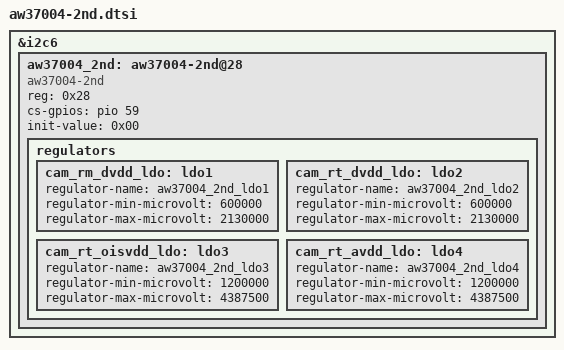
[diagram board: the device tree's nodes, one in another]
&i2c6{
    aw37004_2nd: aw37004-2nd@28 {
        status = "okay";
        compatible = "aw37004-2nd";
        reg = <0x28>;
        cs-gpios = <&pio 59 0>;
        init-value = <0x00>;
        regulators{
            cam_rm_dvdd_ldo: ldo1 {
                regulator-name = "aw37004_2nd_ldo1";
                regulator-min-microvolt = <600000>;
                regulator-max-microvolt = <2130000>;
            };

            cam_rt_dvdd_ldo: ldo2 {
                regulator-name = "aw37004_2nd_ldo2";
                regulator-min-microvolt = <600000>;
                regulator-max-microvolt = <2130000>;

            };

            cam_rt_oisvdd_ldo: ldo3 {
                regulator-name = "aw37004_2nd_ldo3";
                regulator-min-microvolt = <1200000>;
                regulator-max-microvolt = <4387500>;

            };

            cam_rt_avdd_ldo: ldo4 {
                regulator-name = "aw37004_2nd_ldo4";
                regulator-min-microvolt = <1200000>;
                regulator-max-microvolt = <4387500>;

            };
        };
    };
};
